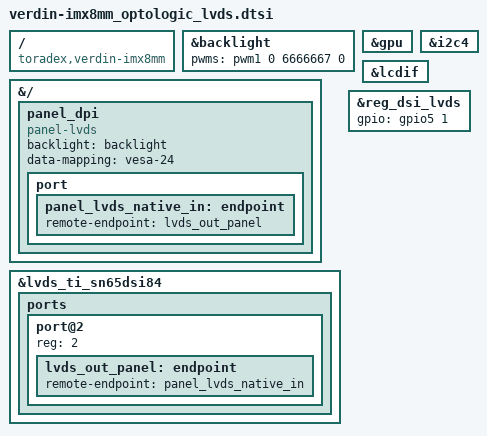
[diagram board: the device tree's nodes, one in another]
// SPDX-License-Identifier: GPL-2.0-or-later OR MIT
/*
 * Common LVDS/backlight/enablement for Verdin iMX8MP Optologic panels
 */

/ {
	compatible = "toradex,verdin-imx8mm";
};

#include "verdin-imx8_mipi-dsi-to-sn65dsi84.dtsi"

&backlight {
	status = "okay";
	/* Verdin PWM_3_DSI/PWM_3_DSI_LVDS (SODIMM 19) */
	pwms = <&pwm1 0 6666667 0>;
};

&gpu {
	status = "okay";
};

/* Verdin I2C_1 */
&i2c4 {
	status = "okay";
};

&lcdif {
	status = "okay";
};

&{/} {
	panel_dpi: panel_dpi { /*name to keep the compatibilty with colibri panel*/
		compatible = "panel-lvds";
		backlight = <&backlight>;
		data-mapping = "vesa-24";
		port {
			panel_lvds_native_in: endpoint {
				remote-endpoint = <&lvds_out_panel>;
			};
		};
	};
};

&lvds_ti_sn65dsi84 {
	status = "okay";

	ports {
		#address-cells = <1>;
		#size-cells = <0>;

		port@2 {
			reg = <2>;

			lvds_out_panel: endpoint {
				remote-endpoint = <&panel_lvds_native_in>;
			};
		};
	};
};

&reg_dsi_lvds {
	/* Verdin CTRL_SLEEP_MOCI# (SODIMM 256) */
	gpio = <&gpio5 1 GPIO_ACTIVE_HIGH>;
};
